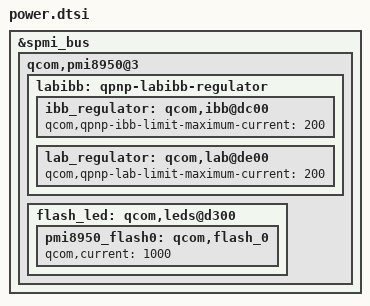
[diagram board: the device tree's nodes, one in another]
/* msm-pm8953 */
&spmi_bus {
	qcom,pmi8950@3 {
		labibb: qpnp-labibb-regulator {
			status = "ok";
			ibb_regulator: qcom,ibb@dc00 {
				qcom,qpnp-ibb-limit-maximum-current = <200>;
			};
			lab_regulator: qcom,lab@de00 {
				qcom,qpnp-lab-limit-maximum-current = <200>;
			};
		};
		flash_led: qcom,leds@d300 {
			pmi8950_flash0: qcom,flash_0 {
				qcom,current = <1000>;
			};
		};
	};
};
